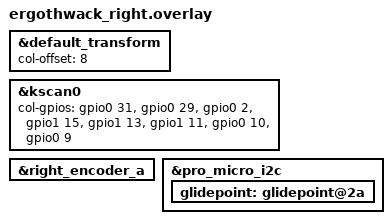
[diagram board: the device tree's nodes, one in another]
#include "ergothwack.dtsi" // Notice that the main dtsi files are included in the overlay.

&default_transform { // The matrix transform for this board is 8 columns over because the left half is 8 columns wide according to the matrix.
    col-offset = <8>;
};

&kscan0 {
    col-gpios
        = <&gpio0 31 GPIO_ACTIVE_HIGH> // col8 in the schematic
        , <&gpio0 29 GPIO_ACTIVE_HIGH> // col9 in the schematic
        , <&gpio0 2 GPIO_ACTIVE_HIGH> // col10 in the schematic
        , <&gpio1 15 GPIO_ACTIVE_HIGH> // col11 in the schematic
        , <&gpio1 13 GPIO_ACTIVE_HIGH> // col12 in the schematic
        , <&gpio1 11 GPIO_ACTIVE_HIGH> // col13 in the schematic
        , <&gpio0 10 GPIO_ACTIVE_HIGH> // col14 in the schematic
        , <&gpio0 9 GPIO_ACTIVE_HIGH> // col15 in the schematic
        ;
};

&right_encoder_a {
    status = "okay";
};

&pro_micro_i2c {
    status = "okay";
    glidepoint: glidepoint@2a {
        status = "okay";
    };
};

/* &i2c0_default {
    group1 {
      bias-pull-up;
    };
}; */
